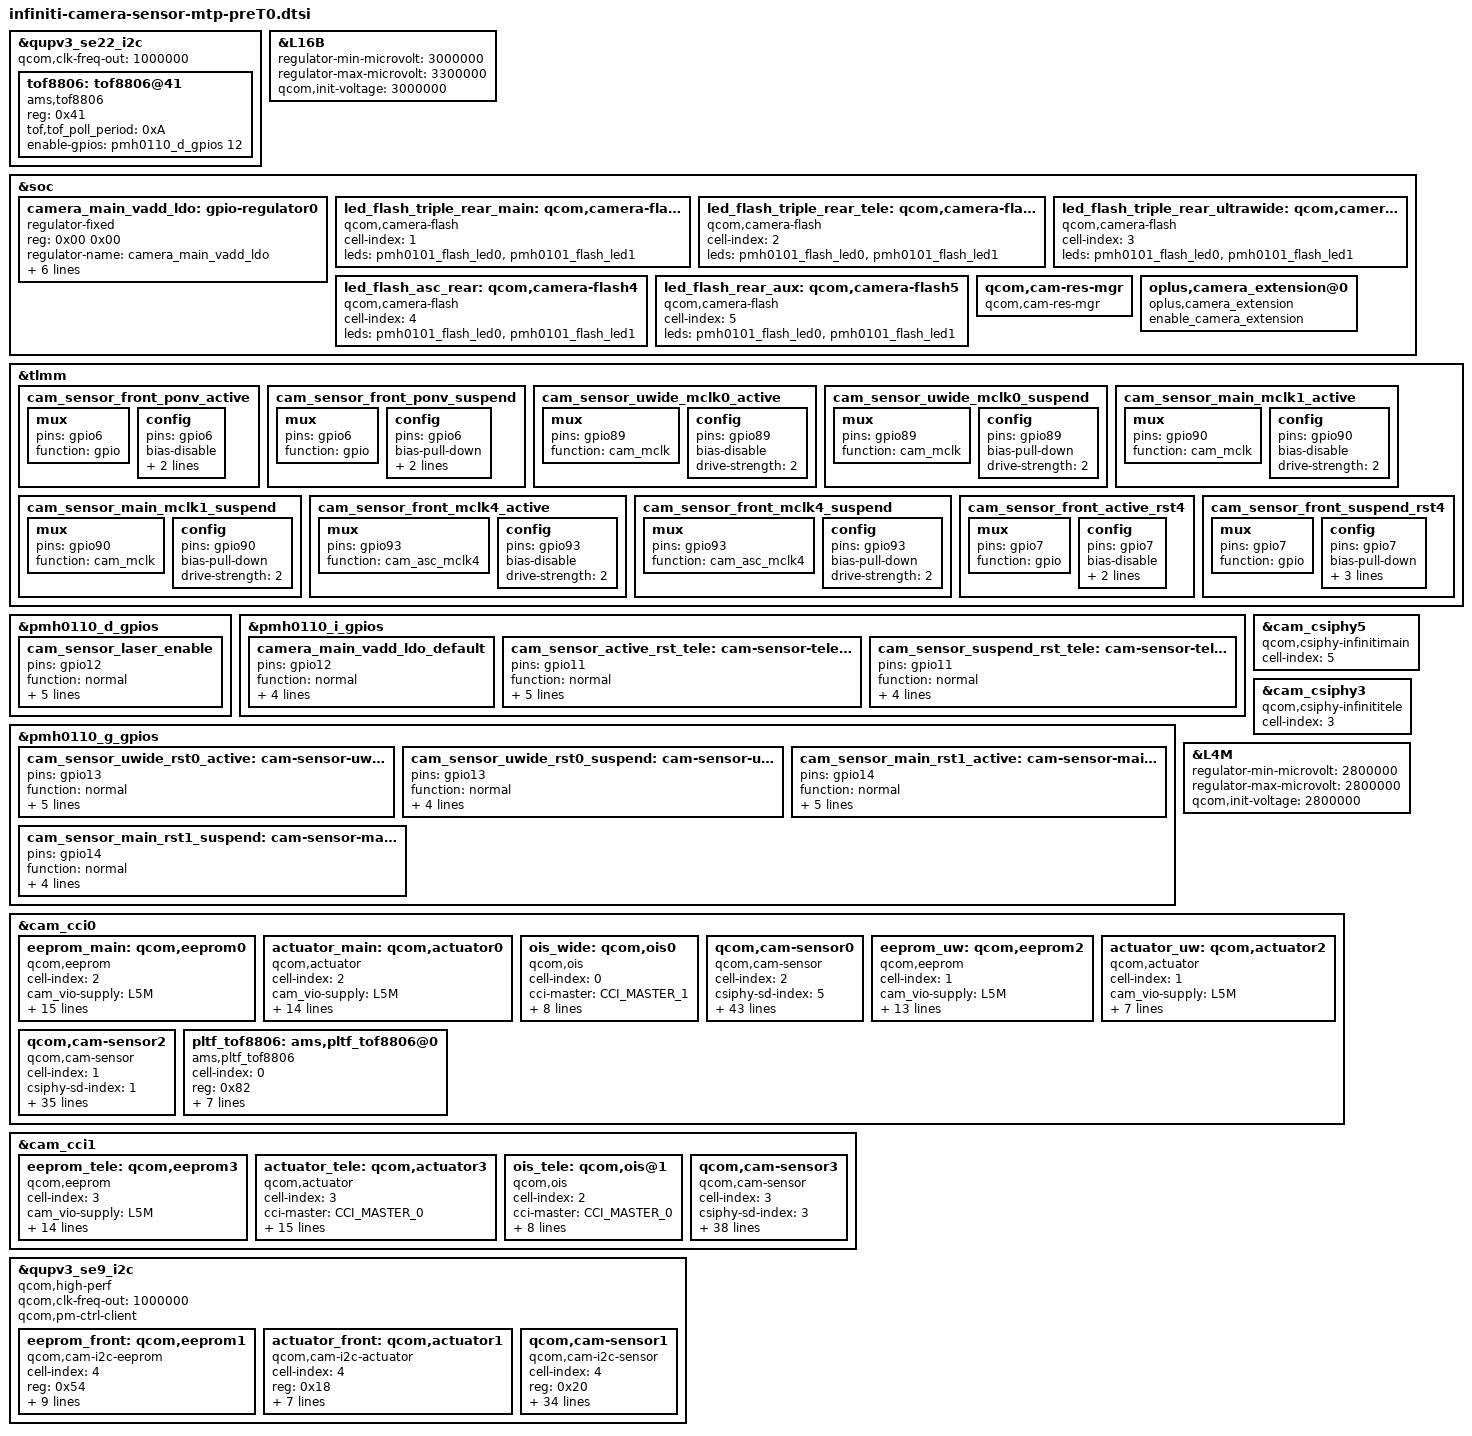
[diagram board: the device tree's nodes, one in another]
// SPDX-License-Identifier: BSD-3-Clause
/*
 * Copyright (c) 2024 Qualcomm Innovation Center, Inc. All rights reserved.
 */

#include <dt-bindings/msm-camera.h>
#include "ftm_camera_settings.dtsi"

&qupv3_se22_i2c {
	status = "ok";
	qcom,clk-freq-out = <1000000>;
	tof8806: tof8806@41 {
		reg = <0x41>;
		tof,tof_poll_period = <0xA>; /*poll period (100 usec)*/
		compatible = "ams,tof8806";
		enable-gpios = <&pmh0110_d_gpios 12 0>;
		status = "ok";
	};
};

&L16B {
	regulator-min-microvolt = <3000000>;
	regulator-max-microvolt = <3300000>;
	qcom,init-voltage = <3000000>;
};

&soc {

	camera_main_vadd_ldo: gpio-regulator0 {
		compatible = "regulator-fixed";
		reg = <0x00 0x00>;
		regulator-name = "camera_main_vadd_ldo";
		regulator-min-microvolt = <1800000>;
		regulator-max-microvolt = <1800000>;
		regulator-enable-ramp-delay = <135>;
		enable-active-high;
		gpio = <&pmh0110_i_gpios 12 0>;
		pinctrl-names = "default";
		pinctrl-0 = <&camera_main_vadd_ldo_default>;
	};

	led_flash_triple_rear_main: qcom,camera-flash1 {
		cell-index = <1>;
		compatible = "qcom,camera-flash";
		leds = <&pmh0101_flash_led0 &pmh0101_flash_led1>;
		status = "ok";
	};

	led_flash_triple_rear_tele: qcom,camera-flash2 {
		cell-index = <2>;
		compatible = "qcom,camera-flash";
		leds = <&pmh0101_flash_led0 &pmh0101_flash_led1>;
		status = "ok";
	};

	led_flash_triple_rear_ultrawide: qcom,camera-flash3 {
		cell-index = <3>;
		compatible = "qcom,camera-flash";
		leds = <&pmh0101_flash_led0 &pmh0101_flash_led1>;
		status = "ok";
	};

	led_flash_asc_rear: qcom,camera-flash4 {
		cell-index = <4>;
		compatible = "qcom,camera-flash";
		leds = <&pmh0101_flash_led0 &pmh0101_flash_led1>;
		status = "ok";
	};

	led_flash_rear_aux: qcom,camera-flash5 {
		cell-index = <5>;
		compatible = "qcom,camera-flash";
		leds = <&pmh0101_flash_led0 &pmh0101_flash_led1>;
		status = "ok";
	};

	qcom,cam-res-mgr {
		compatible = "qcom,cam-res-mgr";
		status = "ok";
	};

	oplus,camera_extension@0 {
		compatible = "oplus,camera_extension";
		enable_camera_extension;
		status = "ok";
	};

};

&tlmm {
	cam_sensor_front_ponv_active: cam_sensor_front_ponv_active {
		/* PONV */
		mux {
			pins = "gpio6";
			function = "gpio";
		};

		config {
			pins = "gpio6";
			bias-disable; /* No PULL */
			output-high;
			drive-strength = <6>; /* 2 MA */
		};
	};

	cam_sensor_front_ponv_suspend: cam_sensor_front_ponv_suspend {
		/* PONV */
		mux {
			pins = "gpio6";
			function = "gpio";
		};

		config {
			pins = "gpio6";


			bias-pull-down; /* PULL DOWN */
			output-low;
			drive-strength = <6>; /* 2 MA */
		};
	};

	cam_sensor_uwide_mclk0_active: cam_sensor_uwide_mclk0_active {
		/* MCLK0 */
		mux {
			pins = "gpio89";
			function = "cam_mclk";
		};

		config {
			pins = "gpio89";
			bias-disable; /* No PULL */
			drive-strength = <2>; /* 2 MA */
		};
	};

	cam_sensor_uwide_mclk0_suspend: cam_sensor_uwide_mclk0_suspend {
		/* MCLK0 */
		mux {
			pins = "gpio89";
			function = "cam_mclk";
		};

		config {
			pins = "gpio89";
			bias-pull-down; /* PULL DOWN */
			drive-strength = <2>; /* 2 MA */
		};
	};

	cam_sensor_main_mclk1_active: cam_sensor_main_mclk1_active {
		/* MCLK1 */
		mux {
			pins = "gpio90";
			function = "cam_mclk";
		};

		config {
			pins = "gpio90";
			bias-disable; /* No PULL */
			drive-strength = <2>; /* 2 MA */
		};
	};

	cam_sensor_main_mclk1_suspend: cam_sensor_main_mclk1_suspend {
		/* MCLK1 */
		mux {
			pins = "gpio90";
			function = "cam_mclk";
		};

		config {
			pins = "gpio90";
			bias-pull-down; /* PULL DOWN */
			drive-strength = <2>; /* 2 MA */
		};
	};

	cam_sensor_front_mclk4_active: cam_sensor_front_mclk4_active {
		/* MCLK4 */
		mux {
			pins = "gpio93";
			function = "cam_asc_mclk4";
		};

		config {
			pins = "gpio93";
			bias-disable; /* No PULL */
			drive-strength = <2>; /* 2 MA */
		};
	};

	cam_sensor_front_mclk4_suspend: cam_sensor_front_mclk4_suspend {
		/* MCLK4 */
		mux {
			pins = "gpio93";
			function = "cam_asc_mclk4";
		};

		config {
			pins = "gpio93";
			bias-pull-down; /* PULL DOWN */
			drive-strength = <2>; /* 2 MA */
		};
	};

	cam_sensor_front_active_rst4: cam_sensor_front_active_rst4 {
		mux {
			pins = "gpio7";
			function = "gpio";
		};

		config {
			pins = "gpio7";
			bias-disable; /* No PULL */
			drive-strength = <2>; /* 2 MA */
			qcom,apps;
		};
	};

	cam_sensor_front_suspend_rst4: cam_sensor_front_suspend_rst4 {
		mux {
			pins = "gpio7";
			function = "gpio";
		};

		config {
			pins = "gpio7";
			bias-pull-down; /* PULL DOWN */
			drive-strength = <2>; /* 2 MA */
			output-low;
			qcom,remote;
		};
	};
};

&pmh0110_d_gpios {

	cam_sensor_laser_enable: cam_sensor_laser_enable {
		pins = "gpio12";
		function = "normal";
		qcom,drive-strength = <2>;
		input-disable;
		output-enable;
		output-high;
		power-source = <1>; /* 1.2 V */
	};
};

&pmh0110_i_gpios {

	camera_main_vadd_ldo_default: camera_main_vadd_ldo_default {
		pins = "gpio12";
		function = "normal";
		input-disable;
		output-low;
		power-source = <1>; /* 2.8V */
		qcom,drive-strength = <2>;
	};

	cam_sensor_active_rst_tele: cam-sensor-tele-active-state {
		pins = "gpio11";
		function = "normal";
		qcom,drive-strength = <2>;
		input-disable;
		output-enable;
		output-high;
		power-source = <1>; /* 1.2 V */
	};

	cam_sensor_suspend_rst_tele: cam-sensor-tele-suspend-state {
		pins = "gpio11";
		function = "normal";
		qcom,drive-strength = <2>;
		input-disable;
		output-enable;
		output-low;
	};
};

&pmh0110_g_gpios {

	cam_sensor_uwide_rst0_active: cam-sensor-uwide-rst0-active-state {
		pins = "gpio13";
		function = "normal";
		qcom,drive-strength = <2>;
		input-disable;
		output-enable;
		output-high;
		power-source = <1>; /* 1.2 V */
	};

	cam_sensor_uwide_rst0_suspend: cam-sensor-uwide-rst0-suspend-state {
		pins = "gpio13";
		function = "normal";
		qcom,drive-strength = <2>;
		input-disable;
		output-enable;
		output-low;
	};

	cam_sensor_main_rst1_active: cam-sensor-main-rst1-active-state {
		pins = "gpio14";
		function = "normal";
		qcom,drive-strength = <2>;
		input-disable;
		output-enable;
		output-high;
		power-source = <1>; /* 1.2 V */
	};

	cam_sensor_main_rst1_suspend: cam-sensor-main-rst1-suspend-state {
		pins = "gpio14";
		function = "normal";
		qcom,drive-strength = <2>;
		input-disable;
		output-enable;
		output-low;
	};
};

&cam_csiphy5{
	cell-index = <5>;
	compatible = "qcom,csiphy-infinitimain", "qcom,csiphy";
};

&cam_csiphy3{
	cell-index = <3>;
	compatible = "qcom,csiphy-infinititele", "qcom,csiphy";
};

&L4M {
  regulator-min-microvolt = <2800000>;
  regulator-max-microvolt = <2800000>;
  qcom,init-voltage = <2800000>;
};

&cam_cci0 {

	eeprom_main: qcom,eeprom0 {
		cell-index = <2>;
		compatible = "qcom,eeprom";
		cam_vio-supply = <&L5M>;
		cam_vdig-supply = <&L2M>;
		power-domains = <&camcc CAM_CC_TITAN_TOP_GDSC>;
		cam_vana-supply = <&L4M>;
		cam_vaf-supply = <&L7M>;
		cam_v_custom1-supply = <&camera_main_vadd_ldo>;
		regulator-names = "cam_vio", "cam_vdig", "cam_vana",
			"cam_vaf", "cam_v_custom1";
		rgltr-cntrl-support;
		rgltr-min-voltage = <1200000 1100000 2800000 2800000 1800000>;
		rgltr-max-voltage = <1200000 1100000 2800000 2800000 1800000>;
		rgltr-load-current = <6000 12000 50000 50000 3000>;
		cci-master = <CCI_MASTER_1>;
		status = "ok";
	};

	actuator_main: qcom,actuator0 {
		cell-index = <2>;
		compatible = "qcom,actuator";
		cam_vio-supply = <&L5M>;
		cam_vaf-supply = <&L7M>;
		regulator-names = "cam_vio", "cam_vaf";
		rgltr-cntrl-support;
		rgltr-min-voltage = <1200000 2800000>;
		rgltr-max-voltage = <1200000 2800000>;
		rgltr-load-current = <6000 50000>;
		cci-master = <CCI_MASTER_1>;
		actuator,name = "dw9827c_main";
		cci_client_sid = <0x18>;
		disable-auto-standby;
		//                                   reg_addr   addr_type   reg_data    data_type   delay       data_mask
		disable-auto-standby-reg-setting = < 0x02           1         0x40        1          5            0x00 >,
		                                   < 0x34           1         0x85        1          1            0x00 >,
		                                   < 0x7D           1         0x00        1          1            0x00 >,
		                                   < 0x03           1         0x01        1          10           0x00 >,
		                                   < 0x34           1         0x52        1          1            0x00 >,
		                                   < 0x04           1         0x01        1          20           0x00 >;
		status = "ok";
	};

	ois_wide: qcom,ois0 {
		cell-index = <0>;
		compatible = "qcom,ois";
		cci-master = <CCI_MASTER_1>;
		cam_vio-supply = <&L5M>;
		cam_vaf-supply = <&L7M>;
		power-domains = <&camcc CAM_CC_TITAN_TOP_GDSC>;
		regulator-names = "cam_vio","cam_vaf";
		rgltr-cntrl-support;
		rgltr-min-voltage = <1200000 2800000>;
		rgltr-max-voltage = <1200000 2800000>;
		rgltr-load-current = <240000 240000>;
		// ois_gyro,position=<3>;
		// ois_gyro,type=<3>;
		// ois,type=<0>;
		// //ois,name="bu63169";//??
		// ois_module,vendor=<1>;
		// ois_actuator,vednor=<2>;
		// ois,fw=<1>;
		status = "ok";
	};

	//main sensor
	qcom,cam-sensor0 {
		cell-index = <2>;
		compatible = "qcom,cam-sensor";
		csiphy-sd-index = <5>;
		sensor-position-roll = <90>;
		sensor-position-pitch = <0>;
		sensor-position-yaw = <180>;
		eeprom-src = <&eeprom_main>;
		actuator-src = <&actuator_main>;
		ois-src = <&ois_wide>;
		led-flash-src = <&led_flash_triple_rear_main>;
		cam_vio-supply = <&L5M>;
		cam_vdig-supply = <&L2M>;
		power-domains = <&camcc CAM_CC_TITAN_TOP_GDSC>;
		cam_vana-supply = <&L4M>;
		cam_vaf-supply = <&L7M>;
		cam_v_custom1-supply = <&camera_main_vadd_ldo>;
		regulator-names = "cam_vio", "cam_vdig", "cam_vana",
			"cam_vaf", "cam_v_custom1";
		rgltr-cntrl-support;
		rgltr-min-voltage = <1200000 1100000 2800000 2800000 1800000>;
		rgltr-max-voltage = <1200000 1100000 2800000 2800000 1800000>;
		rgltr-load-current = <6000 12000 50000 50000 3000>;
		gpio-no-mux = <0>;
		pinctrl-names = "cam_default", "cam_suspend";
		pinctrl-0 = <&cam_sensor_main_mclk1_active
				 &cam_sensor_main_rst1_active>;
		pinctrl-1 = <&cam_sensor_main_mclk1_suspend
				 &cam_sensor_main_rst1_suspend>;
		gpios = <&tlmm 90 0>,
			<&pmh0110_g_gpios 14 0>;
		gpio-reset = <1>;
		gpio-req-tbl-num = <0 1>;
		gpio-req-tbl-flags = <1 0>;
		gpio-req-tbl-label = "CAMIF_MCLK1",
			"CAM_RESET1";
		cci-master = <CCI_MASTER_1>;
		clocks = <&cambistmclkcc CAM_BIST_MCLK_CC_MCLK1_CLK>;
		clock-names = "cam_clk";
		clock-cntl-level = "nominal";
		clock-rates = <19200000>;
		enable_qsc_write_in_advance = <1>;
		qsc_reg_addr = <0x2210>;
		eeprom_slave_addr = <0xA0>;
		qsc_data_size = <3072>;
		write_qsc_addr = <0x1000>;
		ftm_setting_compatible = <'R' 0x0016 2 2 0x0906>;
		status = "ok";
	};

	eeprom_uw: qcom,eeprom2 {
		cell-index = <1>;
		compatible = "qcom,eeprom";
		cam_vio-supply = <&L5M>;
		cam_vdig-supply = <&L1F>;
		power-domains = <&camcc CAM_CC_TITAN_TOP_GDSC>;
		cam_vana-supply = <&L3M>;
		cam_vaf-supply = <&L14B>;
		regulator-names = "cam_vio", "cam_vdig", "cam_vana",
			"cam_vaf";
		rgltr-cntrl-support;
		rgltr-min-voltage = <1200000 1200000 2800000 3200000>;
		rgltr-max-voltage = <1200000 1200000 2900000 3200000>;
		rgltr-load-current = <600000 12000 50000 600000>;
		cci-master = <CCI_MASTER_0>;
		status = "ok";
	};

	actuator_uw: qcom,actuator2 {
		cell-index = <1>;
		compatible = "qcom,actuator";
		cam_vio-supply = <&L5M>;
		cam_vaf-supply = <&L14B>;
		regulator-names = "cam_vio", "cam_vaf";
		rgltr-cntrl-support;
		rgltr-min-voltage = <1200000 3200000>;
		rgltr-max-voltage = <1200000 3200000>;
		rgltr-load-current = <600000 600000>;
		cci-master = <CCI_MASTER_0>;
		status = "ok";
	};

	//ultra wide sensor
	qcom,cam-sensor2 {
		cell-index = <1>;
		compatible = "qcom,cam-sensor";
		csiphy-sd-index = <1>;
		sensor-position-roll = <90>;
		sensor-position-pitch = <0>;
		sensor-position-yaw = <180>;
		eeprom-src = <&eeprom_uw>;
		actuator-src = <&actuator_uw>;
		led-flash-src = <&led_flash_triple_rear_ultrawide>;
		cam_vio-supply = <&L5M>;
		cam_vdig-supply = <&L1F>;
		power-domains = <&camcc CAM_CC_TITAN_TOP_GDSC>;
		cam_vana-supply = <&L3M>;
		cam_vaf-supply = <&L14B>;
		regulator-names = "cam_vio", "cam_vdig", "cam_vana",
			"cam_vaf";
		rgltr-cntrl-support;
		rgltr-min-voltage = <1200000 1200000 2800000 3200000>;
		rgltr-max-voltage = <1200000 1200000 2900000 3200000>;
		rgltr-load-current = <600000 12000 50000 600000>;
		gpio-no-mux = <0>;
		pinctrl-names = "cam_default", "cam_suspend";
		pinctrl-0 = <&cam_sensor_uwide_mclk0_active
				 &cam_sensor_uwide_rst0_active>;
		pinctrl-1 = <&cam_sensor_uwide_mclk0_suspend
				 &cam_sensor_uwide_rst0_suspend>;
		gpios = <&tlmm 89 0>,
			<&pmh0110_g_gpios 13 0>;
		gpio-reset = <1>;
		gpio-req-tbl-num = <0 1>;
		gpio-req-tbl-flags = <1 0>;
		gpio-req-tbl-label = "CAMIF_MCLK0",
			"CAM_RESET0";
		cci-master = <CCI_MASTER_0>;
		clocks = <&cambistmclkcc CAM_BIST_MCLK_CC_MCLK0_CLK>;
		clock-names = "cam_clk";
		clock-cntl-level = "nominal";
		clock-rates = <19200000>;
		ftm_setting_compatible = <'R' 0x300B 2 2 0x5044>;
		status = "ok";
	};

	pltf_tof8806: ams,pltf_tof8806@0 {
		cell-index = <0>;
		reg = <0x82>;
		compatible = "ams,pltf_tof8806";
		cam_vana-supply = <&L16B>;
		regulator-names = "cam_vana";
		rgltr-cntrl-support;
		rgltr-min-voltage = <3000000>;
		rgltr-max-voltage = <3300000>;
		rgltr-load-current = <600000>;
		cci-master = <CCI_MASTER_1>;
		status = "ok";
	};
};

&cam_cci1 {
	eeprom_tele: qcom,eeprom3 {
		cell-index = <3>;
		compatible = "qcom,eeprom";
		cam_vio-supply = <&L5M>;
		cam_vdig-supply = <&L1M>;
		power-domains = <&camcc CAM_CC_TITAN_TOP_GDSC>;
		cam_vana-supply = <&L6M>;
		cam_vaf-supply = <&L16B>;
		regulator-names = "cam_vio", "cam_vdig", "cam_clk","cam_vana","cam_vaf";
		rgltr-cntrl-support;
		rgltr-min-voltage = <1200000 1000000 0 2200000 3300000>;
		rgltr-max-voltage = <1200000 1000000 0 2200000 3300000>;
		rgltr-load-current = <600000 1200000 0 300000 15000>;
		cci-master = <CCI_MASTER_0>;
		status = "ok";
	};

	actuator_tele: qcom,actuator3 {
		cell-index = <3>;
		compatible = "qcom,actuator";
		cci-master = <CCI_MASTER_0>;
		cam_vio-supply = <&L5M>;
		cam_vaf-supply = <&L16B>;
		regulator-names = "cam_vio", "cam_vaf";
		rgltr-cntrl-support;
		rgltr-min-voltage = <1200000 3300000>;
		rgltr-max-voltage = <1200000 3300000>;
		rgltr-load-current = <600000 15000>;
		is_update_pid;
		actuator,name = "dw9827c";
		cci_client_sid = <0x1E>;
		disable-auto-standby;
		//                                   reg_addr   addr_type   reg_data    data_type   delay       data_mask
		disable-auto-standby-reg-setting = < 0x02           1         0x40        1          5            0x00 >,
		                                   < 0x34           1         0x85        1          1            0x00 >,
		                                   < 0x7D           1         0x01        1          1            0x00 >,
		                                   < 0x03           1         0x01        1          10           0x00 >,
		                                   < 0x34           1         0x52        1          1            0x00 >,
		                                   < 0x04           1         0x01        1          20           0x00 >;
		status = "ok";
	};

	ois_tele: qcom,ois@1 {
		cell-index = <2>;
		compatible = "qcom,ois";
		cci-master = <CCI_MASTER_0>;
		cam_vio-supply = <&L16B>;
		cam_vaf-supply = <&L7M>;
		power-domains = <&camcc CAM_CC_TITAN_TOP_GDSC>;
		regulator-names = "cam_vio","cam_vaf";
		rgltr-cntrl-support;
		rgltr-min-voltage = <1800000 2800000>;
		rgltr-max-voltage = <1800000 3000000>;
		rgltr-load-current = <300000 300000>;
		// ois_gyro,position=<3>;
		// ois_gyro,type=<0>;
		// ois,type=<1>;
		// ois,name="sem1217s";
		// ois_module,vendor=<0>;
		// ois_actuator,vednor=<7>;
		// ois,fw=<1>;
		// download,fw=<1>;
		// ois_eis_function = <6>;
		// actuator_ois_eeprom_merge = <1>;
		status = "ok";
	};

	//tele sensor
	qcom,cam-sensor3 {
		cell-index = <3>;
		compatible = "qcom,cam-sensor";
		csiphy-sd-index = <3>;
		sensor-position-roll = <90>;
		sensor-position-pitch = <0>;
		sensor-position-yaw = <180>;
		eeprom-src = <&eeprom_tele>;
		ois-src = <&ois_tele>;
		actuator-src = <&actuator_tele>;
		led-flash-src = <&led_flash_triple_rear_tele>;
		cam_vio-supply = <&L5M>;
		cam_vdig-supply = <&L1M>;
		power-domains = <&camcc CAM_CC_TITAN_TOP_GDSC>;
		cam_vana-supply = <&L6M>;
		cam_vaf-supply = <&L16B>;
		regulator-names = "cam_vio", "cam_vdig", "cam_clk","cam_vana","cam_vaf";
		rgltr-cntrl-support;
		rgltr-min-voltage = <1200000 1000000 0 2200000 3300000>;
		rgltr-max-voltage = <1200000 1000000 0 2200000 3300000>;
		rgltr-load-current = <600000 1200000 0 300000 15000>;
		gpio-no-mux = <0>;
		pinctrl-names = "cam_default", "cam_suspend";
		pinctrl-0 = <&cam_sensor_mclk3_active
				 &cam_sensor_active_rst_tele>;
		pinctrl-1 = <&cam_sensor_mclk3_suspend
				 &cam_sensor_suspend_rst_tele>;
		gpios = <&tlmm 92 0>,
			<&pmh0110_i_gpios 11 0>;
		gpio-reset = <1>;
		gpio-req-tbl-num = <0 1>;
		gpio-req-tbl-flags = <1 0>;
		gpio-req-tbl-label = "CAMIF_MCLK3",
					"CAM_RESET3";
		cci-master = <CCI_MASTER_0>;
		clocks = <&cambistmclkcc CAM_BIST_MCLK_CC_MCLK3_CLK>;
		clock-names = "cam_clk";
		clock-cntl-level = "nominal";
		clock-rates = <19200000>;
		ftm_setting_compatible = <'W' 0xFCFC 2 2 0x4000  'R' 0x0000 2 2 0x38E5>;
		status = "ok";
	};
};

&qupv3_se9_i2c {
	status = "ok";
	qcom,high-perf;
	qcom,clk-freq-out = <1000000>;
	qcom,pm-ctrl-client;

	eeprom_front: qcom,eeprom1 {
		cell-index = <4>;
		reg = <0x54>;
		compatible = "qcom,cam-i2c-eeprom";
		cam_vio-supply = <&L5M>;
		power-domains = <&camcc CAM_CC_TITAN_TOP_GDSC>;
		cam_vana-supply = <&L3M>;
		cam_vaf-supply = <&L7M>;
		regulator-names = "cam_vio", "cam_vana", "cam_vaf";
		rgltr-cntrl-support;
		rgltr-min-voltage = <1200000 2900000 2800000>;
		rgltr-max-voltage = <1200000 2900000 2800000>;
		rgltr-load-current = <3000 50000 50000>;
		status = "ok";
	};

	actuator_front: qcom,actuator1 {
		cell-index = <4>;
		reg = <0x18>;
		compatible = "qcom,cam-i2c-actuator";
		cam_vio-supply = <&L5M>;
		cam_vaf-supply = <&L7M>;
		regulator-names = "cam_vio", "cam_vaf";
		rgltr-cntrl-support;
		rgltr-min-voltage = <1200000 2800000>;
		rgltr-max-voltage = <1200000 2800000>;
		rgltr-load-current = <3000 50000>;
		status = "ok";
	};

	//front sensor
	 qcom,cam-sensor1 {
		cell-index = <4>;
		reg = <0x20>;
		compatible = "qcom,cam-i2c-sensor";
		csiphy-sd-index = <4>;
		sensor-position-roll = <270>;
		sensor-position-pitch = <0>;
		sensor-position-yaw = <180>;
		eeprom-src = <&eeprom_front>;
		actuator-src = <&actuator_front>;
		cam_vio-supply = <&L5M>;
		power-domains = <&camcc CAM_CC_TITAN_TOP_GDSC>;
		cam_vana-supply = <&L3M>;
		cam_vaf-supply = <&L7M>;
		regulator-names = "cam_vio", "cam_vana", "cam_vaf";
		rgltr-cntrl-support;
		aon-camera-id = <AON_CAM1>;
		rgltr-min-voltage = <1200000 2900000 2800000>;
		rgltr-max-voltage = <1200000 2900000 2800000>;
		rgltr-load-current = <3000 50000 50000>;
		gpio-no-mux = <0>;
		pinctrl-names = "cam_default", "cam_suspend";
		pinctrl-0 = <&cam_sensor_front_mclk4_active
				 &cam_sensor_front_active_rst4
				 &cam_sensor_front_ponv_active>;
		pinctrl-1 = <&cam_sensor_front_mclk4_suspend
				 &cam_sensor_front_suspend_rst4
				 &cam_sensor_front_ponv_suspend>;
		gpios = <&tlmm 93 0>,
			<&tlmm 7 0>,
			<&tlmm 6 0>;
		gpio-reset = <1>;
		gpio-req-tbl-num = <0 1 2>;
		gpio-req-tbl-flags = <1 0 0>;
		gpio-req-tbl-label = "CAMIF_MCLK4",
					"CAM_RESET4",
					"CAM_PONV_FRONT";
		clocks = <&cambistmclkcc CAM_BIST_MCLK_CC_MCLK4_CLK>;
		clock-names = "cam_clk";
		clock-cntl-level = "nominal";
		clock-rates = <19200000>;
		ftm_setting_compatible = <'R' 0x0016 2 2 0x0709>;
		status = "ok";
	};
};
